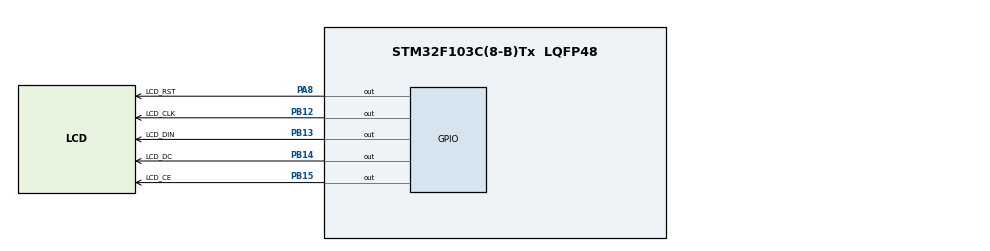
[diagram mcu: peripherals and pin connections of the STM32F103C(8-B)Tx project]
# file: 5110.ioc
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Mcu.Family=STM32F1
Mcu.Name=STM32F103C(8-B)Tx
Mcu.Package=LQFP48
NVIC.PriorityGroup=NVIC_PRIORITYGROUP_4
PA13.Mode=Serial_Wire
PA13.Signal=SYS_JTMS-SWDIO
PA14.Mode=Serial_Wire
PA14.Signal=SYS_JTCK-SWCLK
PA8.GPIO_Label=LCD_RST
PA8.PinState=GPIO_PIN_RESET
PA8.Signal=GPIO_Output
PB12.GPIO_Label=LCD_CLK
PB12.PinState=GPIO_PIN_RESET
PB12.Signal=GPIO_Output
PB13.GPIO_Label=LCD_DIN
PB13.PinState=GPIO_PIN_RESET
PB13.Signal=GPIO_Output
PB14.GPIO_Label=LCD_DC
PB14.PinState=GPIO_PIN_RESET
PB14.Signal=GPIO_Output
PB15.GPIO_Label=LCD_CE
PB15.PinState=GPIO_PIN_RESET
PB15.Signal=GPIO_Output
ProjectManager.HeapSize=0x200
ProjectManager.StackSize=0x400
ProjectManager.TargetToolchain=Makefile
RCC.APB1Freq_Value=8000000
RCC.APB2Freq_Value=8000000
board=5110

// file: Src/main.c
/**
  ******************************************************************************
  * File Name          : main.c
  * Description        : Main program body
  ******************************************************************************
  ** This notice applies to any and all portions of this file
  * that are not between comment pairs USER CODE BEGIN and
  * USER CODE END. Other portions of this file, whether
  * inserted by the user or by software development tools
  * are owned by their respective copyright owners.
  *
  * COPYRIGHT(c) 2017 STMicroelectronics
  *
  * Redistribution and use in source and binary forms, with or without modification,
  * are permitted provided that the following conditions are met:
  *   1. Redistributions of source code must retain the above copyright notice,
  *      this list of conditions and the following disclaimer.
  *   2. Redistributions in binary form must reproduce the above copyright notice,
  *      this list of conditions and the following disclaimer in the documentation
  *      and/or other materials provided with the distribution.
  *   3. Neither the name of STMicroelectronics nor the names of its contributors
  *      may be used to endorse or promote products derived from this software
  *      without specific prior written permission.
  *
  * THIS SOFTWARE IS PROVIDED BY THE COPYRIGHT HOLDERS AND CONTRIBUTORS "AS IS"
  * AND ANY EXPRESS OR IMPLIED WARRANTIES, INCLUDING, BUT NOT LIMITED TO, THE
  * IMPLIED WARRANTIES OF MERCHANTABILITY AND FITNESS FOR A PARTICULAR PURPOSE ARE
  * DISCLAIMED. IN NO EVENT SHALL THE COPYRIGHT HOLDER OR CONTRIBUTORS BE LIABLE
  * FOR ANY DIRECT, INDIRECT, INCIDENTAL, SPECIAL, EXEMPLARY, OR CONSEQUENTIAL
  * DAMAGES (INCLUDING, BUT NOT LIMITED TO, PROCUREMENT OF SUBSTITUTE GOODS OR
  * SERVICES; LOSS OF USE, DATA, OR PROFITS; OR BUSINESS INTERRUPTION) HOWEVER
  * CAUSED AND ON ANY THEORY OF LIABILITY, WHETHER IN CONTRACT, STRICT LIABILITY,
  * OR TORT (INCLUDING NEGLIGENCE OR OTHERWISE) ARISING IN ANY WAY OUT OF THE USE
  * OF THIS SOFTWARE, EVEN IF ADVISED OF THE POSSIBILITY OF SUCH DAMAGE.
  *
  ******************************************************************************
  */
#include "main.h"
#include "stm32f1xx_hal.h"

/* USER CODE BEGIN Includes */
#include "nokia5110_LCD.h"
/* USER CODE END Includes */

/* USER CODE BEGIN PV */
/* Private variables ---------------------------------------------------------*/

/* USER CODE END PV */

void SystemClock_Config(void);
static void MX_GPIO_Init(void);

/* USER CODE BEGIN PFP */
/* Private function prototypes -----------------------------------------------*/

/* USER CODE END PFP */

int main(void)
{

  /* MCU Configuration----------------------------------------------------------*/

  /* Reset of all peripherals, Initializes the Flash interface and the Systick. */
  HAL_Init();

  /* USER CODE BEGIN Init */
  LCD_setRST(GPIOA, LCD_RST_Pin);
  LCD_setCE(GPIOB, LCD_CE_Pin);
  LCD_setDC(GPIOB, LCD_DC_Pin);
  LCD_setDIN(GPIOB, LCD_DIN_Pin);
  LCD_setCLK(GPIOB, LCD_CLK_Pin);
  /* USER CODE END Init */

  /* Configure the system clock */
  SystemClock_Config();

  /* Initialize all configured peripherals */
  MX_GPIO_Init();

  /* USER CODE BEGIN 2 */
  LCD_init();
  /* USER CODE END 2 */

  /* Infinite loop */
  /* USER CODE BEGIN WHILE */
  while (1)
  {
  LCD_clrScr();
  LCD_print("Hello World", 0, 1);
  HAL_Delay(400);
  LCD_print("stm32f103", 0, 2);
  HAL_Delay(400);
  LCD_print("CubeMx", 0, 3);
  HAL_Delay(1000);
  /* USER CODE END WHILE */

  }

}

/** System Clock Configuration
*/
void SystemClock_Config(void)
{

  RCC_OscInitTypeDef RCC_OscInitStruct;
  RCC_ClkInitTypeDef RCC_ClkInitStruct;

    /**Initializes the CPU, AHB and APB busses clocks
    */
  RCC_OscInitStruct.OscillatorType = RCC_OSCILLATORTYPE_HSI;
  RCC_OscInitStruct.HSIState = RCC_HSI_ON;
  RCC_OscInitStruct.HSICalibrationValue = 16;
  RCC_OscInitStruct.PLL.PLLState = RCC_PLL_NONE;
  if (HAL_RCC_OscConfig(&RCC_OscInitStruct) != HAL_OK)
  {
    _Error_Handler(__FILE__, __LINE__);
  }

    /**Initializes the CPU, AHB and APB busses clocks
    */
  RCC_ClkInitStruct.ClockType = RCC_CLOCKTYPE_HCLK|RCC_CLOCKTYPE_SYSCLK
                              |RCC_CLOCKTYPE_PCLK1|RCC_CLOCKTYPE_PCLK2;
  RCC_ClkInitStruct.SYSCLKSource = RCC_SYSCLKSOURCE_HSI;
  RCC_ClkInitStruct.AHBCLKDivider = RCC_SYSCLK_DIV1;
  RCC_ClkInitStruct.APB1CLKDivider = RCC_HCLK_DIV1;
  RCC_ClkInitStruct.APB2CLKDivider = RCC_HCLK_DIV1;

  if (HAL_RCC_ClockConfig(&RCC_ClkInitStruct, FLASH_LATENCY_0) != HAL_OK)
  {
    _Error_Handler(__FILE__, __LINE__);
  }

    /**Configure the Systick interrupt time
    */
  HAL_SYSTICK_Config(HAL_RCC_GetHCLKFreq()/1000);

    /**Configure the Systick
    */
  HAL_SYSTICK_CLKSourceConfig(SYSTICK_CLKSOURCE_HCLK);

  /* SysTick_IRQn interrupt configuration */
  HAL_NVIC_SetPriority(SysTick_IRQn, 0, 0);
}

/** Configure pins as
        * Analog
        * Input
        * Output
        * EVENT_OUT
        * EXTI
*/
static void MX_GPIO_Init(void)
{

  GPIO_InitTypeDef GPIO_InitStruct;

  /* GPIO Ports Clock Enable */
  __HAL_RCC_GPIOB_CLK_ENABLE();
  __HAL_RCC_GPIOA_CLK_ENABLE();

  /*Configure GPIO pin Output Level */
  HAL_GPIO_WritePin(GPIOB, LCD_CLK_Pin|LCD_DIN_Pin|LCD_DC_Pin|LCD_CE_Pin, GPIO_PIN_RESET);

  /*Configure GPIO pin Output Level */
  HAL_GPIO_WritePin(LCD_RST_GPIO_Port, LCD_RST_Pin, GPIO_PIN_RESET);

  /*Configure GPIO pins : LCD_CLK_Pin LCD_DIN_Pin LCD_DC_Pin LCD_CE_Pin */
  GPIO_InitStruct.Pin = LCD_CLK_Pin|LCD_DIN_Pin|LCD_DC_Pin|LCD_CE_Pin;
  GPIO_InitStruct.Mode = GPIO_MODE_OUTPUT_PP;
  GPIO_InitStruct.Speed = GPIO_SPEED_FREQ_LOW;
  HAL_GPIO_Init(GPIOB, &GPIO_InitStruct);

  /*Configure GPIO pin : LCD_RST_Pin */
  GPIO_InitStruct.Pin = LCD_RST_Pin;
  GPIO_InitStruct.Mode = GPIO_MODE_OUTPUT_PP;
  GPIO_InitStruct.Speed = GPIO_SPEED_FREQ_LOW;
  HAL_GPIO_Init(LCD_RST_GPIO_Port, &GPIO_InitStruct);

}

void _Error_Handler(char * file, int line)
{
  while(1)
  {
  }
}

/************************ (C) COPYRIGHT STMicroelectronics *****END OF FILE****/
